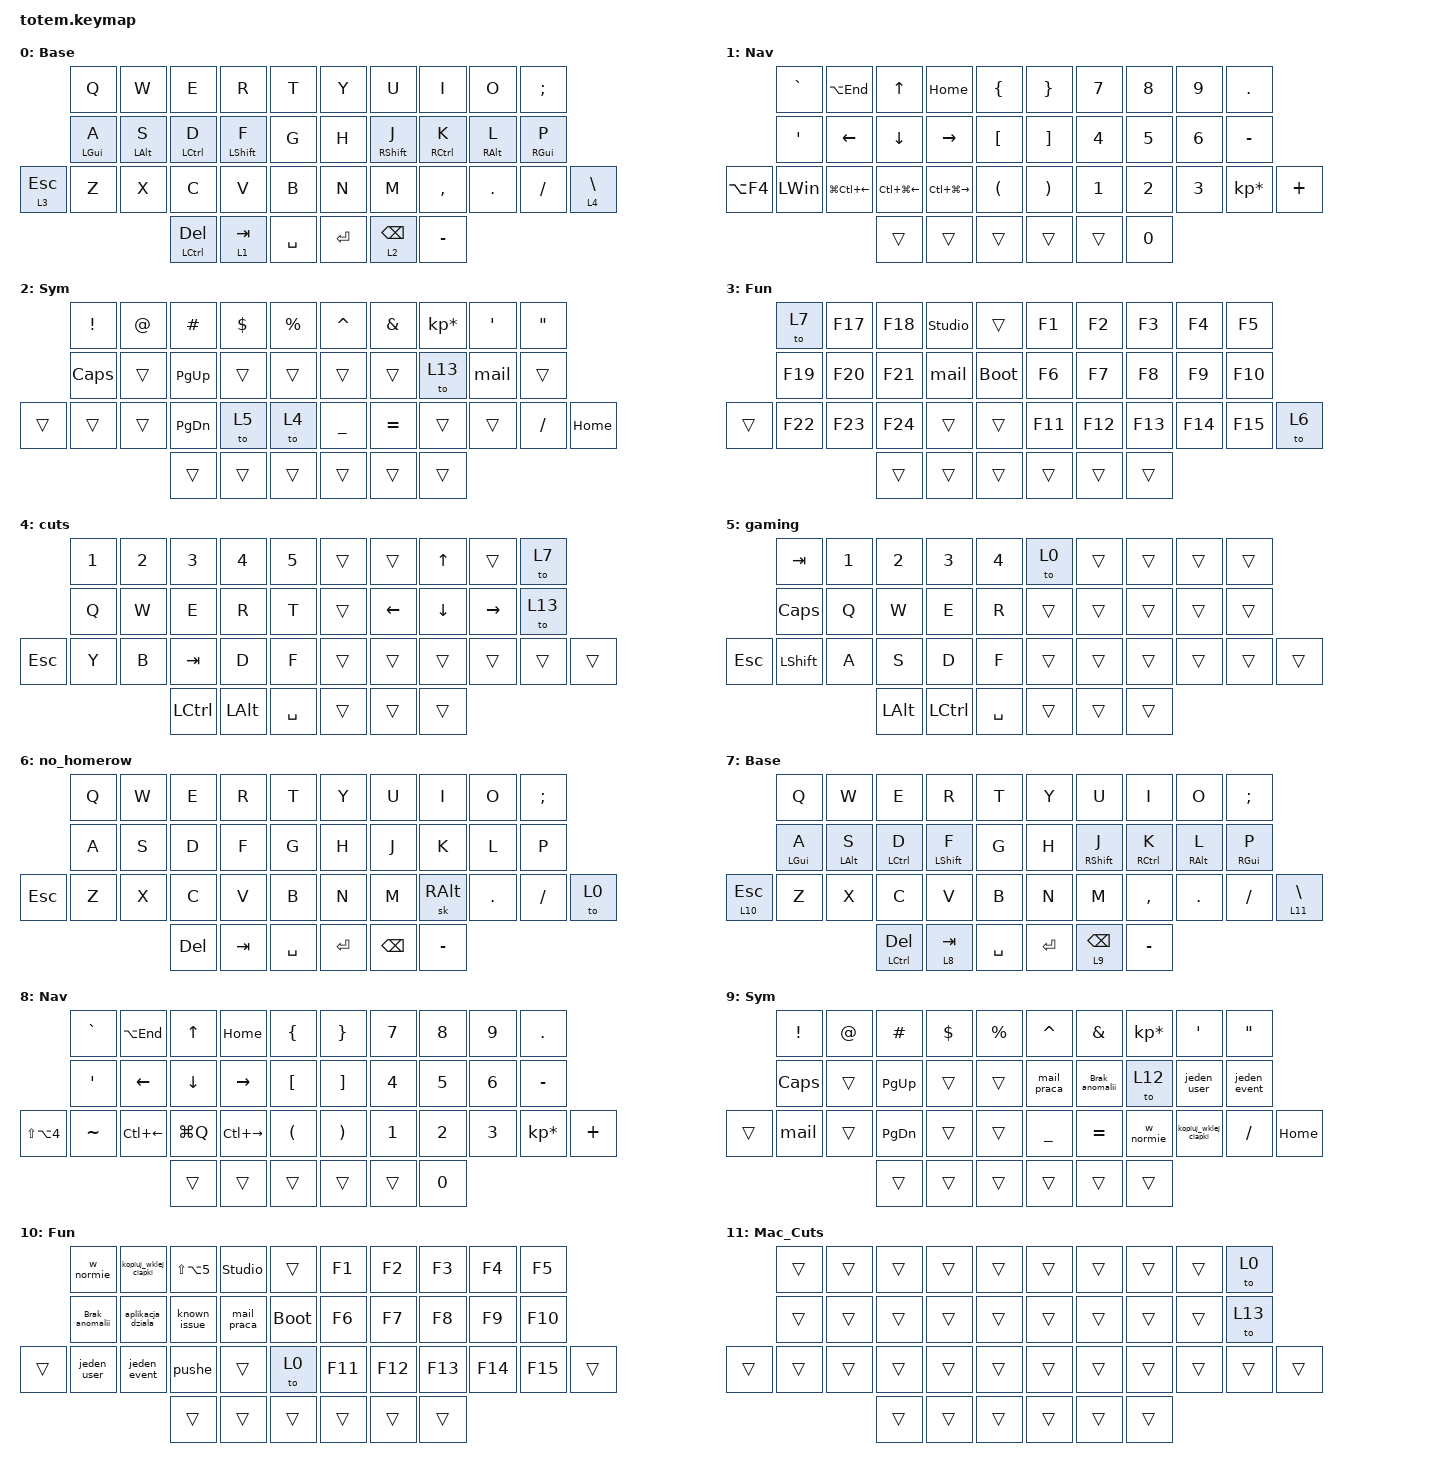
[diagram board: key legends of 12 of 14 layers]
//
//                                                        ▀▀▀▀▀     ▀▀▀▀▀          ▀▀█▀▀
//                                                        ▄▀▀▀▄  ▄  ▄▀▀▀▄  ▄  ▄▀▀▀▄  █  ▄▀▀▀▄
//                                                        █   █  █  █   █  █  █   █  █  █   █
//                                                         ▀▀▀   █   ▀▀▀   █   ▀▀▀   ▀   ▀▀▀
//                                                               █      ▄▄▄█▄▄▄    █   █  
//                                                               ▀      █  █  █     █▄█
//                                                             ▀▀▀▀▀    █  █  █      ▀
//                                                                      ▀  ▀  ▀
//
// ▄▄▄▄▄▄▄▄▄▄▄▄▄▄▄▄▄▄▄▄▄▄▄▄▄▄▄▄▄▄▄▄▄▄▄▄▄▄▄▄▄▄▄▄▄▄▄▄▄▄▄▄▄▄▄▄▄▄▄▄▄▄▄▄▄▄▄▄▄▄▄▄▄▄▄▄▄▄▄▄▄▄▄▄▄▄▄▄▄▄▄▄▄▄▄▄▄▄▄▄▄▄▄▄▄▄▄▄▄▄▄▄▄▄▄▄▄▄▄▄▄▄▄▄▄▄▄▄▄▄▄▄▄▄▄▄▄▄▄▄▄▄▄▄▄▄▄▄▄

#define ZMK_POINTING_DEFAULT_MOVE_VAL 3000
#define ZMK_POINTING_DEFAULT_SCRL_VAL 40

#include <behaviors.dtsi>
#include <dt-bindings/zmk/keys.h>
#include <dt-bindings/zmk/pointing.h>

#define Base        0
#define Nav         1
#define Sym         2
#define Fun         3
#define Game        4
#define Gameplus    5

&mt {
    quick-tap-ms = <100>;
    global-quick-tap;
    flavor = "tap-preferred";
    tapping-term-ms = <170>;
};

&lt {
    tapping-term-ms = <240>;
    flavor = "balanced";
    quick-tap-ms = <150>;
};

/ {
    behaviors {
        hm: homerow_mods {
            compatible = "zmk,behavior-hold-tap";
            label = "HOMEROW_MODS";
            #binding-cells = <2>;
            flavor = "tap-preferred";
            tapping-term-ms = <200>;
            quick-tap-ms = <125>;
            global-quick-tap;
            bindings = <&kp>, <&kp>;
        };
    };

    combos { compatible = "zmk,combos"; };

    macros {
        Brak_anomalii: Brak_anomalii {
            compatible = "zmk,behavior-macro";
            #binding-cells = <0>;
            bindings = <&kp B &kp R &kp A &kp K &kp SPACE &kp A &kp N &kp O &kp M &kp A &kp L &kp I &kp I &kp TAB &kp ENTER>;
            label = "BRAK_ANOMALII";
        };

        w_normie: w_normie {
            compatible = "zmk,behavior-macro";
            #binding-cells = <0>;
            bindings = <&kp W &kp SPACE &kp N &kp O &kp R &kp M &kp I &kp E &kp TAB &kp ENTER>;
            label = "W_NORMIE";
        };

        jeden_user: jeden_user {
            compatible = "zmk,behavior-macro";
            #binding-cells = <0>;
            bindings = <&kp N1 &kp SPACE &kp U &kp S &kp E &kp R &kp TAB &kp ENTER>;
            label = "JEDEN_USER";
        };

        kopiuj_wklej_ciapki: kopiuj_wklej_ciapki {
            compatible = "zmk,behavior-macro";
            #binding-cells = <0>;
            bindings = <&kp LA(A) &kp DELETE &kp DOUBLE_QUOTES &kp LA(V) &kp DOUBLE_QUOTES &kp ENTER>;
            label = "KOPIUJ_WKLEJ_CIAPKI";
        };

        mail_praca: mail_praca {
            compatible = "zmk,behavior-macro";
            #binding-cells = <0>;
            bindings = <&kp M &kp DOT &kp P &kp Y &kp C &kp K &kp A &kp AT &kp F &kp U &kp T &kp U &kp R &kp E &kp M &kp I &kp N &kp D &kp DOT &kp C &kp O &kp M>;
            label = "MAIL_PRACA";
        };

        mail: mail {
            compatible = "zmk,behavior-macro";
            #binding-cells = <0>;
            bindings = <&kp P &kp Y &kp C &kp K &kp A &kp M &kp A &kp T &kp E &kp U &kp S &kp Z &kp AT &kp P &kp M &kp DOT &kp M &kp E>;
            label = "MAIL";
        };

        aplikacja_dziala: aplikacja_dziala {
            compatible = "zmk,behavior-macro";
            #binding-cells = <0>;
            bindings = <&kp A &kp P &kp L &kp I &kp K &kp A &kp C &kp J &kp A &kp SPACE &kp D &kp Z &kp I &kp A &kp A &kp TAB &kp ENTER>;
            label = "APLIKACJA_DZIALA";
        };

        jeden_event: jeden_event {
            compatible = "zmk,behavior-macro";
            #binding-cells = <0>;
            bindings = <&kp N1 &kp SPACE &kp E &kp V &kp E &kp N &kp T &kp TAB &kp ENTER>;
            label = "JEDEN_EVENT";
        };

        pushe: pushe {
            compatible = "zmk,behavior-macro";
            #binding-cells = <0>;
            bindings = <&kp P &kp U &kp S &kp H &kp E &kp TAB &kp ENTER>;
            label = "PUSHE";
        };

        known_issue: known_issue {
            compatible = "zmk,behavior-macro";
            #binding-cells = <0>;
            bindings = <&kp K &kp N &kp O &kp W &kp N &kp SPACE &kp I &kp S &kp S &kp U &kp E &kp TAB &kp ENTER>;
            label = "KNOWN_ISSUE";
        };
    };

    keymap {
        compatible = "zmk,keymap";

        Base {
            display-name = "Base";
            bindings = <
              &kp Q       &kp W       &kp E          &kp R         &kp T        &kp Y    &kp U        &kp I        &kp O       &kp SEMICOLON
              &hm LGUI A  &hm LALT S  &hm LCTRL D    &hm LSHIFT F  &kp G        &kp H    &hm RSHFT J  &hm RCTRL K  &hm RALT L  &hm RGUI P
&lt 3 ESCAPE  &kp Z       &kp X       &kp C          &kp V         &kp B        &kp N    &kp M        &kp COMMA    &kp DOT     &kp SLASH      &lt 4 BACKSLASH
                                      &mt LCTRL DEL  &lt 1 TAB     &kp SPACE    &kp RET  &lt 2 BSPC   &kp MINUS
            >;
        };

        Nav {
            display-name = "Nav";
            bindings = <
            &kp GRAVE     &kp LA(END)             &kp UP_ARROW            &kp HOME                 &kp LBRC    &kp RBRC  &kp NUMBER_7  &kp NUMBER_8  &kp NUMBER_9  &kp DOT
            &kp APOS      &kp LEFT                &kp DOWN                &kp RIGHT                &kp LBKT    &kp RBKT  &kp NUMBER_4  &kp NUMBER_5  &kp NUMBER_6  &kp MINUS
&kp LA(F4)  &kp LEFT_WIN  &kp LG(LC(LEFT_ARROW))  &kp LC(LG(LEFT_ARROW))  &kp LC(LG(RIGHT_ARROW))  &kp LPAR    &kp RPAR  &kp NUMBER_1  &kp NUMBER_2  &kp NUMBER_3  &kp KP_MULTIPLY  &kp PLUS
                                                  &trans                  &trans                   &trans      &trans    &trans        &kp NUMBER_0
            >;
        };

        Sym {
            display-name = "Sym";
            bindings = <
        &kp EXCL  &kp AT  &kp HASH       &kp DOLLAR  &kp PERCENT    &kp CARET  &kp AMPERSAND  &kp KP_ASTERISK  &kp SQT  &kp DQT
        &kp CAPS  &trans  &kp PAGE_UP    &trans      &trans         &trans     &trans         &to 13           &mail    &trans
&trans  &trans    &trans  &kp PAGE_DOWN  &to 5       &to 4          &kp UNDER  &kp EQUAL      &trans           &trans   &kp SLASH  &kp HOME
                          &trans         &trans      &trans         &trans     &trans         &trans
            >;
        };

        Fun {
            display-name = "Fun";
            bindings = <
        &to 7    &kp F17  &kp F18  &studio_unlock  &trans         &kp F1   &kp F2   &kp F3   &kp F4   &kp F5
        &kp F19  &kp F20  &kp F21  &mail           &bootloader    &kp F6   &kp F7   &kp F8   &kp F9   &kp F10
&trans  &kp F22  &kp F23  &kp F24  &trans          &trans         &kp F11  &kp F12  &kp F13  &kp F14  &kp F15  &to 6
                          &trans   &trans          &trans         &trans   &trans   &trans
            >;
        };

        cuts {
            bindings = <
         &kp N1  &kp N2  &kp N3     &kp N4    &kp N5       &trans  &trans    &kp UP    &trans     &to 7
         &kp Q   &kp W   &kp E      &kp R     &kp T        &trans  &kp LEFT  &kp DOWN  &kp RIGHT  &to 13
&kp ESC  &kp Y   &kp B   &kp TAB    &kp D     &kp F        &trans  &trans    &trans    &trans     &trans  &trans
                         &kp LCTRL  &kp LALT  &kp SPACE    &trans  &trans    &trans
            >;
        };

        gaming {
            bindings = <
         &kp TAB    &kp N1  &kp N2    &kp N3     &kp N4       &to 0   &trans  &trans  &trans  &trans
         &kp CAPS   &kp Q   &kp W     &kp E      &kp R        &trans  &trans  &trans  &trans  &trans
&kp ESC  &kp LSHFT  &kp A   &kp S     &kp D      &kp F        &trans  &trans  &trans  &trans  &trans  &trans
                            &kp LALT  &kp LCTRL  &kp SPACE    &trans  &trans  &trans
            >;
        };

        no_homerow {
            bindings = <
         &kp Q  &kp W  &kp E    &kp R    &kp T        &kp Y    &kp U     &kp I      &kp O    &kp SEMI
         &kp A  &kp S  &kp D    &kp F    &kp G        &kp H    &kp J     &kp K      &kp L    &kp P
&kp ESC  &kp Z  &kp X  &kp C    &kp V    &kp B        &kp N    &kp M     &sk RALT   &kp DOT  &kp FSLH  &to 0
                       &kp DEL  &kp TAB  &kp SPACE    &kp RET  &kp BSPC  &kp MINUS
            >;
        };

        mac {
            display-name = "Base";
            bindings = <
               &kp Q       &kp W       &kp E          &kp R         &kp T        &kp Y    &kp U        &kp I        &kp O       &kp SEMICOLON
               &hm LGUI A  &hm LALT S  &hm LCTRL D    &hm LSHIFT F  &kp G        &kp H    &hm RSHFT J  &hm RCTRL K  &hm RALT L  &hm RGUI P
&lt 10 ESCAPE  &kp Z       &kp X       &kp C          &kp V         &kp B        &kp N    &kp M        &kp COMMA    &kp DOT     &kp SLASH      &lt 11 BACKSLASH
                                       &mt LCTRL DEL  &lt 8 TAB     &kp SPACE    &kp RET  &lt 9 BSPC   &kp MINUS
            >;
        };

        mac_nav {
            display-name = "Nav";
            bindings = <
                      &kp GRAVE  &kp LA(END)         &kp UP_ARROW  &kp HOME             &kp LBRC    &kp RBRC  &kp NUMBER_7  &kp NUMBER_8  &kp NUMBER_9  &kp DOT
                      &kp APOS   &kp LEFT            &kp DOWN      &kp RIGHT            &kp LBKT    &kp RBKT  &kp NUMBER_4  &kp NUMBER_5  &kp NUMBER_6  &kp MINUS
&kp LS(LA(NUMBER_4))  &kp TILDE  &kp LC(LEFT_ARROW)  &kp LG(Q)     &kp LC(RIGHT_ARROW)  &kp LPAR    &kp RPAR  &kp NUMBER_1  &kp NUMBER_2  &kp NUMBER_3  &kp KP_MULTIPLY  &kp PLUS
                                                     &trans        &trans               &trans      &trans    &trans        &kp NUMBER_0
            >;
        };

        Mac_Sym {
            display-name = "Sym";
            bindings = <
        &kp EXCL  &kp AT  &kp HASH       &kp DOLLAR  &kp PERCENT    &kp CARET    &kp AMPERSAND   &kp KP_ASTERISK  &kp SQT               &kp DQT
        &kp CAPS  &trans  &kp PAGE_UP    &trans      &trans         &mail_praca  &Brak_anomalii  &to 12           &jeden_user           &jeden_event
&trans  &mail     &trans  &kp PAGE_DOWN  &trans      &trans         &kp UNDER    &kp EQUAL       &w_normie        &kopiuj_wklej_ciapki  &kp SLASH     &kp HOME
                          &trans         &trans      &trans         &trans       &trans          &trans
            >;
        };

        mac_fun {
            display-name = "Fun";
            bindings = <
        &w_normie       &kopiuj_wklej_ciapki  &kp LS(LA(NUMBER_5))  &studio_unlock  &trans         &kp F1   &kp F2   &kp F3   &kp F4   &kp F5
        &Brak_anomalii  &aplikacja_dziala     &known_issue          &mail_praca     &bootloader    &kp F6   &kp F7   &kp F8   &kp F9   &kp F10
&trans  &jeden_user     &jeden_event          &pushe                &trans          &to 0          &kp F11  &kp F12  &kp F13  &kp F14  &kp F15  &trans
                                              &trans                &trans          &trans         &trans   &trans   &trans
            >;
        };

        Mac_Cuts {
            bindings = <
        &trans  &trans  &trans  &trans  &trans    &trans  &trans  &trans  &trans  &to 0
        &trans  &trans  &trans  &trans  &trans    &trans  &trans  &trans  &trans  &to 13
&trans  &trans  &trans  &trans  &trans  &trans    &trans  &trans  &trans  &trans  &trans  &trans
                        &trans  &trans  &trans    &trans  &trans  &trans
            >;
        };

        mouse_mac {
            display-name = "Base";
            bindings = <
               &kp Q       &kp W       &kp E          &kp R         &kp T        &msc SCRL_LEFT  &mkp LCLK       &mmv MOVE_UP    &mkp RCLK        &msc SCRL_RIGHT
               &hm LGUI A  &hm LALT S  &hm LCTRL D    &hm LSHIFT F  &kp G        &to 7           &mmv MOVE_LEFT  &mmv MOVE_DOWN  &mmv MOVE_RIGHT  &hm RGUI P
&lt 10 ESCAPE  &kp Z       &kp X       &kp C          &kp V         &kp B        &kp N           &msc SCRL_UP    &mkp MCLK       &msc SCRL_DOWN   &kp SLASH        &lt 11 BACKSLASH
                                       &mt LCTRL DEL  &lt 8 TAB     &kp SPACE    &kp RET         &lt 9 BSPC      &kp MINUS
            >;
        };

        mouse {
            bindings = <
        &trans  &trans  &trans  &trans  &trans    &msc SCRL_LEFT  &mkp LCLK       &mmv MOVE_UP    &mkp RCLK        &msc SCRL_RIGHT
        &trans  &trans  &trans  &trans  &trans    &to 0           &mmv MOVE_LEFT  &mmv MOVE_DOWN  &mmv MOVE_RIGHT  &trans
&trans  &trans  &trans  &trans  &trans  &trans    &trans          &msc SCRL_UP    &mkp MCLK       &msc SCRL_DOWN   &trans           &trans
                        &trans  &trans  &trans    &trans          &trans          &trans
            >;
        };
    };
};
